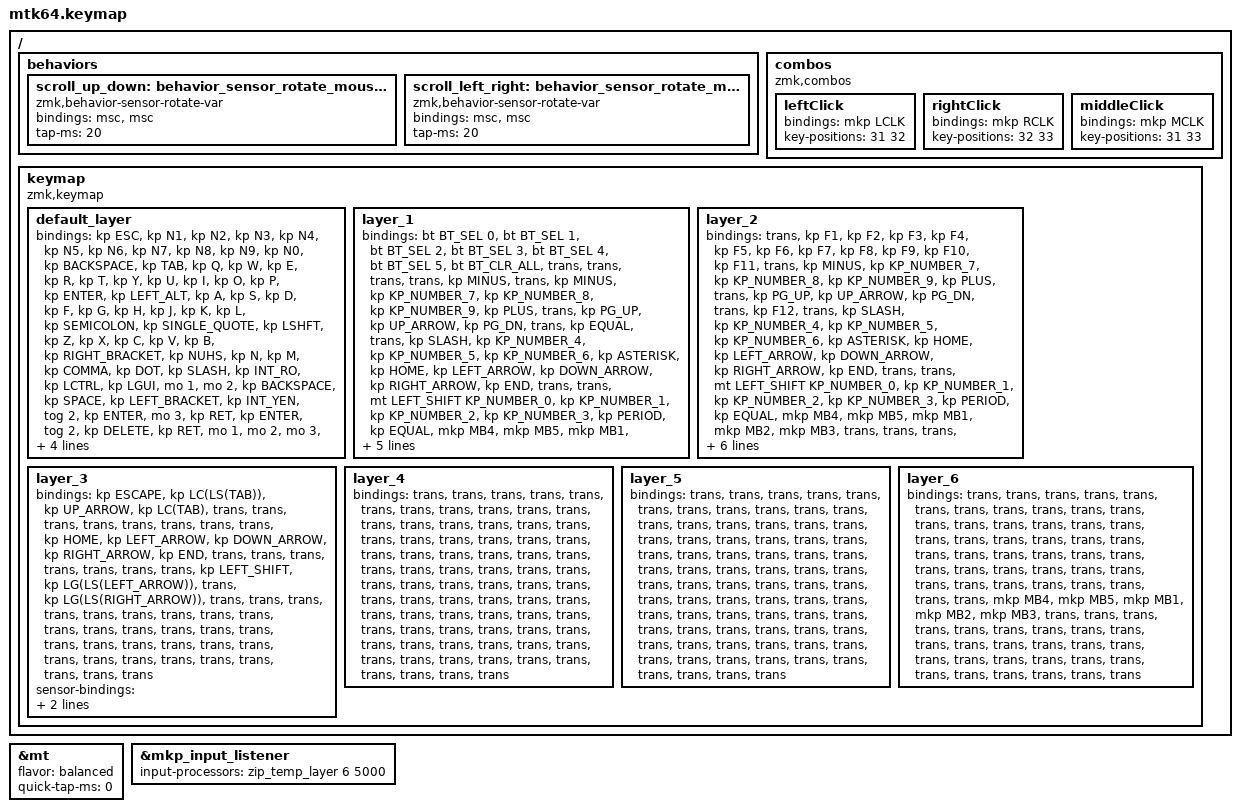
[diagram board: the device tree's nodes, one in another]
#include <input/processors.dtsi>
#include <behaviors.dtsi>
#include <dt-bindings/zmk/bt.h>
#include <dt-bindings/zmk/keys.h>
#include <dt-bindings/zmk/pointing.h>
#include "keycode_japanese.h"

// スクロール量の設定

#define ZMK_POINTING_DEFAULT_SCRL_VAL 100

&mt {
    flavor = "balanced";
    quick-tap-ms = <0>;
};

&mkp_input_listener { input-processors = <&zip_temp_layer 6 5000>; };

/ {
    behaviors {
        // 垂直スクロール用のbehaviorの設定

        scroll_up_down: behavior_sensor_rotate_mouse_wheel_up_down {
            compatible = "zmk,behavior-sensor-rotate-var";
            #sensor-binding-cells = <2>;
            bindings = <&msc>, <&msc>;

            tap-ms = <20>; // スクロールのタップ時間
        };

        // 水平スクロール用のbehaviorの設定

        scroll_left_right: behavior_sensor_rotate_mouse_wheel_left_right {
            compatible = "zmk,behavior-sensor-rotate-var";
            #sensor-binding-cells = <2>;
            bindings = <&msc>, <&msc>;

            tap-ms = <20>; // スクロールのタップ時間
        };
    };
};

/ {
    combos {
        compatible = "zmk,combos";

        leftClick {
            bindings = <&mkp LCLK>;
            key-positions = <31 32>;
        };

        rightClick {
            bindings = <&mkp RCLK>;
            key-positions = <32 33>;
        };

        middleClick {
            bindings = <&mkp MCLK>;
            key-positions = <31 33>;
        };
    };

    keymap {
        compatible = "zmk,keymap";

        default_layer {
            bindings = <
&kp ESC  &kp N1  &kp N2  &kp N3  &kp N4  &kp N5  &kp N6  &kp N7  &kp N8  &kp N9  &kp N0  &kp BACKSPACE  &kp TAB  &kp Q  &kp W  &kp E  &kp R  &kp T  &kp Y  &kp U  &kp I  &kp O  &kp P  &kp ENTER  &kp LEFT_ALT  &kp A  &kp S  &kp D  &kp F  &kp G  &kp H  &kp J  &kp K  &kp L  &kp SEMICOLON  &kp SINGLE_QUOTE  &kp LSHFT  &kp Z  &kp X  &kp C  &kp V  &kp B  &kp RIGHT_BRACKET  &kp NUHS  &kp N  &kp M  &kp COMMA  &kp DOT  &kp SLASH  &kp INT_RO  &kp LCTRL  &kp LGUI  &mo 1  &mo 2  &kp BACKSPACE  &kp SPACE  &kp LEFT_BRACKET  &kp INT_YEN  &tog 2  &kp ENTER  &mo 3  &kp RET  &kp ENTER  &tog 2  &kp DELETE  &kp RET  &mo 1  &mo 2  &mo 3  &mo 1  &mo 2  &mo 3  &mo 1  &mo 2  &mo 3
            >;

            sensor-bindings =
                <&scroll_up_down SCRL_UP SCRL_DOWN>,
                <&scroll_left_right SCRL_RIGHT SCRL_LEFT>;
        };

        layer_1 {
            bindings = <
&bt BT_SEL 0  &bt BT_SEL 1  &bt BT_SEL 2  &bt BT_SEL 3  &bt BT_SEL 4  &bt BT_SEL 5  &bt BT_CLR_ALL  &trans  &trans  &trans  &trans  &kp MINUS  &trans  &kp MINUS  &kp KP_NUMBER_7  &kp KP_NUMBER_8  &kp KP_NUMBER_9  &kp PLUS  &trans  &kp PG_UP  &kp UP_ARROW  &kp PG_DN  &trans  &kp EQUAL  &trans  &kp SLASH  &kp KP_NUMBER_4  &kp KP_NUMBER_5  &kp KP_NUMBER_6  &kp ASTERISK  &kp HOME  &kp LEFT_ARROW  &kp DOWN_ARROW  &kp RIGHT_ARROW  &kp END  &trans  &trans  &mt LEFT_SHIFT KP_NUMBER_0  &kp KP_NUMBER_1  &kp KP_NUMBER_2  &kp KP_NUMBER_3  &kp PERIOD  &kp EQUAL  &mkp MB4  &mkp MB5  &mkp MB1  &mkp MB2  &mkp MB3  &trans  &trans  &trans  &trans  &trans  &trans  &trans  &trans  &trans  &trans  &trans  &trans  &trans  &trans  &trans  &trans  &trans  &trans  &trans  &trans  &trans  &trans  &trans  &trans  &trans  &trans  &trans
            >;
        };

        layer_2 {
            bindings = <
&trans  &kp F1  &kp F2  &kp F3  &kp F4  &kp F5  &kp F6  &kp F7  &kp F8  &kp F9  &kp F10  &kp F11  &trans  &kp MINUS  &kp KP_NUMBER_7  &kp KP_NUMBER_8  &kp KP_NUMBER_9  &kp PLUS  &trans  &kp PG_UP  &kp UP_ARROW  &kp PG_DN  &trans  &kp F12  &trans  &kp SLASH  &kp KP_NUMBER_4  &kp KP_NUMBER_5  &kp KP_NUMBER_6  &kp ASTERISK  &kp HOME  &kp LEFT_ARROW  &kp DOWN_ARROW  &kp RIGHT_ARROW  &kp END  &trans  &trans  &mt LEFT_SHIFT KP_NUMBER_0  &kp KP_NUMBER_1  &kp KP_NUMBER_2  &kp KP_NUMBER_3  &kp PERIOD  &kp EQUAL  &mkp MB4  &mkp MB5  &mkp MB1  &mkp MB2  &mkp MB3  &trans  &trans  &trans  &trans  &trans  &trans  &trans  &trans  &trans  &trans  &trans  &trans  &trans  &trans  &trans  &trans  &trans  &trans  &trans  &trans  &trans  &trans  &trans  &trans  &trans  &trans  &trans
            >;

            sensor-bindings = <
                &inc_dec_kp TAB LS(TAB) 
                &inc_dec_kp PG_UP PG_DN
            >;
        };

        layer_3 {
            bindings = <
&kp ESCAPE  &kp LC(LS(TAB))  &kp UP_ARROW  &kp LC(TAB)  &trans  &trans  &trans  &trans  &trans  &trans  &trans  &trans  &kp HOME  &kp LEFT_ARROW  &kp DOWN_ARROW  &kp RIGHT_ARROW  &kp END  &trans  &trans  &trans  &trans  &trans  &trans  &trans  &kp LEFT_SHIFT  &kp LG(LS(LEFT_ARROW))  &trans  &kp LG(LS(RIGHT_ARROW))  &trans  &trans  &trans  &trans  &trans  &trans  &trans  &trans  &trans  &trans  &trans  &trans  &trans  &trans  &trans  &trans  &trans  &trans  &trans  &trans  &trans  &trans  &trans  &trans  &trans  &trans  &trans  &trans  &trans  &trans
            >;

            sensor-bindings = <
                &scroll_left_right SCRL_LEFT SCRL_RIGHT
                &scroll_up_down SCRL_UP SCRL_DOWN
            >;
        };

        layer_4 {
            bindings = <
&trans  &trans  &trans  &trans  &trans  &trans  &trans  &trans  &trans  &trans  &trans  &trans  &trans  &trans  &trans  &trans  &trans  &trans  &trans  &trans  &trans  &trans  &trans  &trans  &trans  &trans  &trans  &trans  &trans  &trans  &trans  &trans  &trans  &trans  &trans  &trans  &trans  &trans  &trans  &trans  &trans  &trans  &trans  &trans  &trans  &trans  &trans  &trans  &trans  &trans  &trans  &trans  &trans  &trans  &trans  &trans  &trans  &trans  &trans  &trans  &trans  &trans  &trans  &trans  &trans  &trans  &trans  &trans  &trans  &trans  &trans  &trans  &trans  &trans  &trans
            >;
        };

        layer_5 {
            bindings = <
&trans  &trans  &trans  &trans  &trans  &trans  &trans  &trans  &trans  &trans  &trans  &trans  &trans  &trans  &trans  &trans  &trans  &trans  &trans  &trans  &trans  &trans  &trans  &trans  &trans  &trans  &trans  &trans  &trans  &trans  &trans  &trans  &trans  &trans  &trans  &trans  &trans  &trans  &trans  &trans  &trans  &trans  &trans  &trans  &trans  &trans  &trans  &trans  &trans  &trans  &trans  &trans  &trans  &trans  &trans  &trans  &trans  &trans  &trans  &trans  &trans  &trans  &trans  &trans  &trans  &trans  &trans  &trans  &trans  &trans  &trans  &trans  &trans  &trans  &trans
            >;
        };

        layer_6 {
            bindings = <
&trans  &trans  &trans  &trans  &trans  &trans  &trans  &trans  &trans  &trans  &trans  &trans  &trans  &trans  &trans  &trans  &trans  &trans  &trans  &trans  &trans  &trans  &trans  &trans  &trans  &trans  &trans  &trans  &trans  &trans  &trans  &trans  &trans  &trans  &trans  &trans  &trans  &trans  &trans  &trans  &trans  &trans  &trans  &mkp MB4  &mkp MB5  &mkp MB1  &mkp MB2  &mkp MB3  &trans  &trans  &trans  &trans  &trans  &trans  &trans  &trans  &trans  &trans  &trans  &trans  &trans  &trans  &trans  &trans  &trans  &trans  &trans  &trans  &trans  &trans  &trans  &trans  &trans  &trans  &trans
            >;
        };
    };
};
